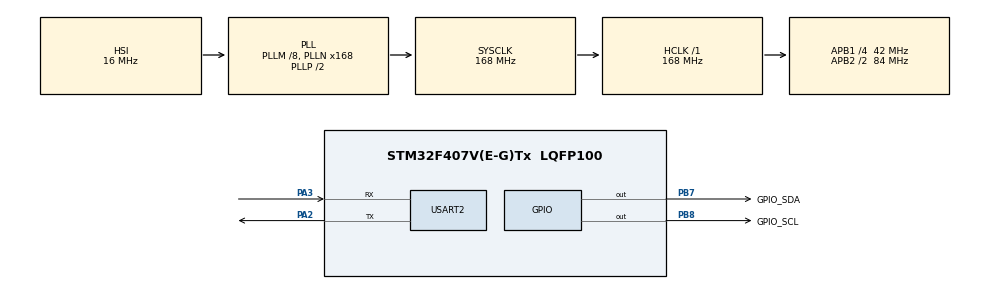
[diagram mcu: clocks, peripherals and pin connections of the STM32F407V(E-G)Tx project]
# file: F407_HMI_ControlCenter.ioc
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Dma.Request0=USART2_RX
Dma.Request1=USART2_TX
Dma.USART2_RX.0.Direction=DMA_PERIPH_TO_MEMORY
Dma.USART2_RX.0.FIFOMode=DMA_FIFOMODE_DISABLE
Dma.USART2_RX.0.Instance=DMA1_Stream5
Dma.USART2_RX.0.MemDataAlignment=DMA_MDATAALIGN_BYTE
Dma.USART2_RX.0.MemInc=DMA_MINC_ENABLE
Dma.USART2_RX.0.Mode=DMA_NORMAL
Dma.USART2_RX.0.PeriphDataAlignment=DMA_PDATAALIGN_BYTE
Dma.USART2_RX.0.PeriphInc=DMA_PINC_DISABLE
Dma.USART2_RX.0.Priority=DMA_PRIORITY_LOW
Dma.USART2_TX.1.Direction=DMA_MEMORY_TO_PERIPH
Dma.USART2_TX.1.FIFOMode=DMA_FIFOMODE_DISABLE
Dma.USART2_TX.1.Instance=DMA1_Stream6
Dma.USART2_TX.1.MemDataAlignment=DMA_MDATAALIGN_BYTE
Dma.USART2_TX.1.MemInc=DMA_MINC_ENABLE
Dma.USART2_TX.1.Mode=DMA_NORMAL
Dma.USART2_TX.1.PeriphDataAlignment=DMA_PDATAALIGN_BYTE
Dma.USART2_TX.1.PeriphInc=DMA_PINC_DISABLE
Dma.USART2_TX.1.Priority=DMA_PRIORITY_LOW
Mcu.Family=STM32F4
Mcu.Name=STM32F407V(E-G)Tx
Mcu.Package=LQFP100
NVIC.DMA1_Stream5_IRQn=true\:0\:0\:false\:false\:true\:false\:true\:true
NVIC.DMA1_Stream6_IRQn=true\:0\:0\:false\:false\:true\:false\:true\:true
NVIC.PriorityGroup=NVIC_PRIORITYGROUP_4
NVIC.USART2_IRQn=true\:0\:0\:false\:false\:true\:true\:true\:true
PA13.Mode=Serial_Wire
PA13.Signal=SYS_JTMS-SWDIO
PA14.Mode=Serial_Wire
PA14.Signal=SYS_JTCK-SWCLK
PA2.Mode=Asynchronous
PA2.Signal=USART2_TX
PA3.Mode=Asynchronous
PA3.Signal=USART2_RX
PB7.GPIO_Label=GPIO_SDA
PB7.GPIO_ModeDefaultOutputPP=GPIO_MODE_OUTPUT_PP
PB7.GPIO_Speed=GPIO_SPEED_FREQ_MEDIUM
PB7.PinState=GPIO_PIN_RESET
PB7.Signal=GPIO_Output
PB8.GPIO_Label=GPIO_SCL
PB8.GPIO_Speed=GPIO_SPEED_FREQ_MEDIUM
PB8.PinState=GPIO_PIN_RESET
PB8.Signal=GPIO_Output
ProjectManager.HeapSize=0x200
ProjectManager.StackSize=0x400
ProjectManager.TargetToolchain=MDK-ARM V5.32
RCC.48MHZClocksFreq_Value=84000000
RCC.AHBFreq_Value=168000000
RCC.APB1CLKDivider=RCC_HCLK_DIV4
RCC.APB1Freq_Value=42000000
RCC.APB1TimFreq_Value=84000000
RCC.APB2CLKDivider=RCC_HCLK_DIV2
RCC.APB2Freq_Value=84000000
RCC.APB2TimFreq_Value=168000000
RCC.CortexFreq_Value=168000000
RCC.HCLKFreq_Value=168000000
RCC.HSE_VALUE=25000000
RCC.HSI_VALUE=16000000
RCC.LSE_VALUE=32768
RCC.PLLM=8
RCC.PLLN=168
RCC.SYSCLKFreq_VALUE=168000000
RCC.SYSCLKSource=RCC_SYSCLKSOURCE_PLLCLK
RCC.VCOOutputFreq_Value=336000000
USART2.VirtualMode=VM_ASYNC
board=custom

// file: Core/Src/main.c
/* USER CODE BEGIN Header */
/**
  ******************************************************************************
  * @file           : main.c
  * @brief          : Main program body
  ******************************************************************************
  * @attention
  *
  * Copyright (c) 2026 STMicroelectronics.
  * All rights reserved.
  *
  * This software is licensed under terms that can be found in the LICENSE file
  * in the root directory of this software component.
  * If no LICENSE file comes with this software, it is provided AS-IS.
  *
  ******************************************************************************
  */
/* USER CODE END Header */
#include "main.h"
#include "dma.h"
#include "usart.h"
#include "gpio.h"

/* USER CODE BEGIN Includes */
#include "OLED.h"
#include "OLED_Data.h"
#include "se_protocol.h"
/* USER CODE END Includes */

void SystemClock_Config(void);

int main(void)
{

  /* MCU Configuration--------------------------------------------------------*/

  /* Reset of all peripherals, Initializes the Flash interface and the Systick. */
  HAL_Init();

  /* Configure the system clock */
  SystemClock_Config();

  /* Initialize all configured peripherals */
  MX_GPIO_Init();
  MX_DMA_Init();
  MX_USART2_UART_Init();
  /* USER CODE BEGIN 2 */
	OLED_Init();
// 1. 初始化我们的协议库
  SE_Protocol_Init();
  /* USER CODE END 2 */

  /* Infinite loop */
  while (1)
  {

    /* USER CODE BEGIN 3 */
		/* 在 X=0, Y=0 的位置，用 8x16 字体显示，%d 会被替换成变量的值 */
    OLED_Printf(0, 0, OLED_8X16, "VaL: %.2f    ", g_latest_sensor_val);
    OLED_Update(); // 别忘了刷新屏幕！
  }
  /* USER CODE END 3 */
}

void SystemClock_Config(void)
{
  RCC_OscInitTypeDef RCC_OscInitStruct = {0};
  RCC_ClkInitTypeDef RCC_ClkInitStruct = {0};

  /** Configure the main internal regulator output voltage
  */
  __HAL_RCC_PWR_CLK_ENABLE();
  __HAL_PWR_VOLTAGESCALING_CONFIG(PWR_REGULATOR_VOLTAGE_SCALE1);

  /** Initializes the RCC Oscillators according to the specified parameters
  * in the RCC_OscInitTypeDef structure.
  */
  RCC_OscInitStruct.OscillatorType = RCC_OSCILLATORTYPE_HSI;
  RCC_OscInitStruct.HSIState = RCC_HSI_ON;
  RCC_OscInitStruct.HSICalibrationValue = RCC_HSICALIBRATION_DEFAULT;
  RCC_OscInitStruct.PLL.PLLState = RCC_PLL_ON;
  RCC_OscInitStruct.PLL.PLLSource = RCC_PLLSOURCE_HSI;
  RCC_OscInitStruct.PLL.PLLM = 8;
  RCC_OscInitStruct.PLL.PLLN = 168;
  RCC_OscInitStruct.PLL.PLLP = RCC_PLLP_DIV2;
  RCC_OscInitStruct.PLL.PLLQ = 4;
  if (HAL_RCC_OscConfig(&RCC_OscInitStruct) != HAL_OK)
  {
    Error_Handler();
  }

  /** Initializes the CPU, AHB and APB buses clocks
  */
  RCC_ClkInitStruct.ClockType = RCC_CLOCKTYPE_HCLK|RCC_CLOCKTYPE_SYSCLK
                              |RCC_CLOCKTYPE_PCLK1|RCC_CLOCKTYPE_PCLK2;
  RCC_ClkInitStruct.SYSCLKSource = RCC_SYSCLKSOURCE_PLLCLK;
  RCC_ClkInitStruct.AHBCLKDivider = RCC_SYSCLK_DIV1;
  RCC_ClkInitStruct.APB1CLKDivider = RCC_HCLK_DIV4;
  RCC_ClkInitStruct.APB2CLKDivider = RCC_HCLK_DIV2;

  if (HAL_RCC_ClockConfig(&RCC_ClkInitStruct, FLASH_LATENCY_5) != HAL_OK)
  {
    Error_Handler();
  }
}

/* USER CODE BEGIN 4 */
void HAL_UARTEx_RxEventCallback(UART_HandleTypeDef *huart, uint16_t Size)
{
    if (huart == &huart2) {
        // Size 是本次 DMA 实际搬运进来的字节数
        // 1. 将接收到的这批数据，一股脑塞进状态机解析
        SE_Protocol_ParseBuffer(dma_rx_buffer, Size);

        // 2. 解析完后，重新启动 DMA 接收下一批数据！(这一步绝对不能漏)
        HAL_UARTEx_ReceiveToIdle_DMA(&huart2, dma_rx_buffer, RX_BUFFER_SIZE);
        __HAL_DMA_DISABLE_IT(huart2.hdmarx, DMA_IT_HT);
    }
}
/* USER CODE END 4 */

void Error_Handler(void)
{
  __disable_irq();
  while (1)
  {
  }
}
